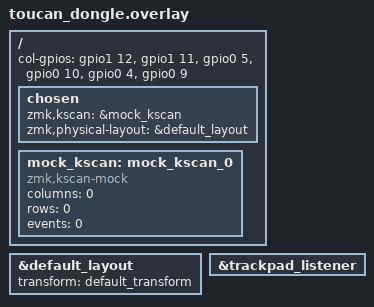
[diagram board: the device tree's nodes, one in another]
#include "toucan.dtsi"

/ {
    chosen {
        zmk,kscan = &mock_kscan;
        zmk,physical-layout = &default_layout;
    };

    mock_kscan: mock_kscan_0 {
        compatible = "zmk,kscan-mock";
        columns = <0>;
        rows = <0>;
        events = <0>;
    };

    col-gpios
        = <&gpio1 12 GPIO_ACTIVE_HIGH>
        , <&gpio1 11 GPIO_ACTIVE_HIGH>
        , <&gpio0 5 GPIO_ACTIVE_HIGH>
        , <&gpio0 10 GPIO_ACTIVE_HIGH>
        , <&gpio0 4 GPIO_ACTIVE_HIGH>
        , <&gpio0 9 GPIO_ACTIVE_HIGH>
        ;
};

 &default_layout {
     transform = <&default_transform>;
 };

&trackpad_listener {
    status = "okay";
};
